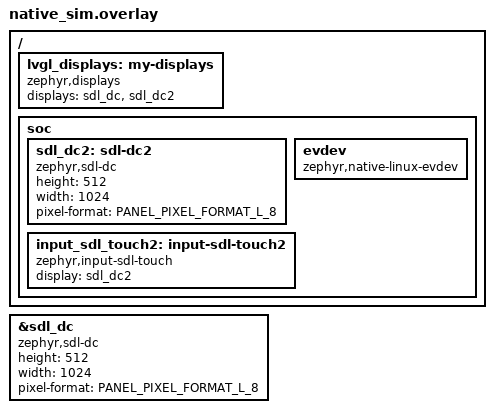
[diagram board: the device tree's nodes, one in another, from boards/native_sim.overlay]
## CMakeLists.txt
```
cmake_minimum_required(VERSION 3.20.0)

find_package(Zephyr REQUIRED HINTS $ENV{ZEPHYR_BASE})
project(3d_game_template_demo)

target_sources(app PRIVATE src/main.c src/editor_render.c src/editor_UI.c)

zephyr_include_directories(include)

set(TOOLS_FOLDER ${CMAKE_CURRENT_SOURCE_DIR}/../../../zephyr_3d_game_template2/tools)

add_custom_command(
OUTPUT generated/generated_objects.h
COMMAND python3 ${CMAKE_CURRENT_SOURCE_DIR}/generate_objects.py ${TOOLS_FOLDER} ${CMAKE_CURRENT_SOURCE_DIR}/${CONFIG_DATA_PATH} generated
WORKING_DIRECTORY ${CMAKE_CURRENT_BINARY_DIR}
)

add_custom_target(generate_objects DEPENDS generated/generated_objects.h)

zephyr_include_directories(${CMAKE_CURRENT_BINARY_DIR}/generated)

add_dependencies(app generate_objects)
```

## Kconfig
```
menu "Zephyr"
source "Kconfig.zephyr"
endmenu

module = VISUALIZER
module-str = VISUALIZER
source "subsys/logging/Kconfig.template.log_config"
```

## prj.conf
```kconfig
CONFIG_DISPLAY=y
CONFIG_LOG=y
CONFIG_ENGINE=y
#CONFIG_LOG_DEFAULT_LEVEL=4
CONFIG_HEAP_MEM_POOL_SIZE=65536
CONFIG_INPUT=y
CONFIG_MAIN_STACK_SIZE=65536
CONFIG_TIMING_FUNCTIONS=y
CONFIG_SPEED_OPTIMIZATIONS=y
CONFIG_LOG_PERFORMANCE=n
CONFIG_TEST_RANDOM_GENERATOR=y
CONFIG_TIMER_RANDOM_GENERATOR=y
CONFIG_GPIO=y
CONFIG_MAX_OBJECTS=1048576
CONFIG_BLIT_THREAD=n

CONFIG_LVGL=y
CONFIG_LV_USE_LOG=y
CONFIG_LV_Z_MEM_POOL_SIZE=131072
CONFIG_SYS_HEAP_RUNTIME_STATS=y

CONFIG_LV_FONT_MONTSERRAT_12=y
CONFIG_LV_Z_FLUSH_THREAD=y
CONFIG_LV_FONT_UNSCII_8=y

CONFIG_JSON_LIBRARY=y
#CONFIG_FLASH=y
#CONFIG_FILE_SYSTEM=y
#CONFIG_FUSE_FS_ACCESS=y
#CONFIG_FLASH_SIMULATOR=y
CONFIG_DATA_PATH="../../data"
```

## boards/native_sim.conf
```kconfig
CONFIG_SDL_DISPLAY_ZOOM_PCT=250
#CONFIG_SDL_DISPLAY_ZOOM_PCT=400
#CONFIG_SDL_DISPLAY_DEFAULT_PIXEL_FORMAT_RGB_565=y
CONFIG_RESOLUTION_X=1024
CONFIG_RESOLUTION_Y=512
CONFIG_TARGET_PROCESS_FPS=30
CONFIG_TARGET_RENDER_FPS=30
CONFIG_SYS_CLOCK_TICKS_PER_SEC=1000
```

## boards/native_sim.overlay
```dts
#include <zephyr/dt-bindings/input/input-event-codes.h>

&sdl_dc {
	compatible = "zephyr,sdl-dc";
	height = <512>;
	width = <1024>;
	pixel-format = <PANEL_PIXEL_FORMAT_L_8>;
};

/ {
	/delete-property/ zephyr,display;

	lvgl_displays: my-displays {
		compatible = "zephyr,displays";
		displays = <&sdl_dc &sdl_dc2>;
		status = "okay";
	};

	soc {
		sdl_dc2: sdl-dc2 {
			compatible = "zephyr,sdl-dc";
			height = <512>;
			width = <1024>;
			pixel-format = <PANEL_PIXEL_FORMAT_L_8>;
		};
		evdev: evdev {
			compatible = "zephyr,native-linux-evdev";
		};
		input_sdl_touch2: input-sdl-touch2 {
			compatible = "zephyr,input-sdl-touch";
			display = <&sdl_dc2>;
		};
	};
};
```

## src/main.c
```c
#include <zephyr/kernel.h>
#include <zephyr/device.h>
#include <zephyr/drivers/display.h>
#include <zephyr/input/input.h>
#include <zephyr/timing/timing.h>
#include <stdio.h>
#include <stdlib.h>
#include <zephyr/random/random.h>
#include <math.h>

#include <zephyr/logging/log.h>
LOG_MODULE_REGISTER(main);

#include "editor.h"

#include "engine.h"

L3_COLORTYPE blit_lvgl_buffer[L3_RESOLUTION_X * L3_RESOLUTION_Y];

int blit_display(L3_COLORTYPE *buffer, uint16_t x, uint16_t y, uint16_t size_x, uint16_t size_y)
{	/*struct display_buffer_descriptor buf_desc;
	buf_desc.buf_size = size_x * size_y;
		buf_desc.width = size_x;
	buf_desc.height = size_y;
	buf_desc.pitch = size_x;
		display_write(display_devices[0], 0, 0, &buf_desc, buffer);*/
	memcpy(blit_lvgl_buffer + x + y * L3_RESOLUTION_X, buffer, size_x*size_y);
	return 0;
}

typedef struct {
	L3_Unit vx;
	L3_Unit vy;
	L3_Unit z;
	L3_Unit x;
	L3_Unit speedmul;
	L3_Unit jump;
	L3_Unit xrot;
} Controls;

static Engine_Object* player = 0;
static Controls controls = {0};

static void process() {
	if (player != 0) {
		player->visual.transform.rotation.y += controls.vy;
		player->visual.transform.rotation.x += controls.vx;
		if (player->visual.transform.rotation.y > L3_F/2) player->visual.transform.rotation.y = -L3_F/2;
		if (player->visual.transform.rotation.y < -L3_F/2) player->visual.transform.rotation.y = L3_F/2;
		if (player->visual.transform.rotation.x > L3_F/2) player->visual.transform.rotation.x = -L3_F/2;
		if (player->visual.transform.rotation.x < -L3_F/2) player->visual.transform.rotation.x = L3_F/2;

		L3_Vec4 forward = {0, 0, L3_F, L3_F};
		L3_Vec4 left = {-L3_F, 0, 0, L3_F};
		L3_Mat4 transMat;

		L3_makeRotationMatrixZXY(player->visual.transform.rotation.x,
							player->visual.transform.rotation.y,
							0,
							transMat);

		L3_vec3Xmat4(&forward, transMat);
		L3_vec3Xmat4(&left, transMat);

		player->visual.transform.translation.x += controls.z * forward.x / L3_F;
		player->visual.transform.translation.y += controls.z * forward.y / L3_F;
		player->visual.transform.translation.z += controls.z * forward.z / L3_F;
		player->visual.transform.translation.x += controls.x * left.x / L3_F;
		player->visual.transform.translation.y += controls.x * left.y / L3_F;
		player->visual.transform.translation.z += controls.x * left.z / L3_F;

		L3_Camera *camera = engine_getcamera();
		camera->transform = player->visual.transform;
#ifdef CONFIG_SDL_DISPLAY
		printf("\r\b%d %d %d %d %d %d      ",
			camera->transform.translation.x,
			camera->transform.translation.y,
			camera->transform.translation.z,
			camera->transform.rotation.x,
			camera->transform.rotation.y,
			camera->transform.rotation.z);
#endif
	}

	do_editor_UI();
}

static void update_controls(struct input_event *evt, void *user_data)
{
	Controls *cont = user_data;

	if (evt->code == INPUT_KEY_UP) {
		if (evt->value)
			cont->vx = 5;
		else
			cont->vx = 0;
	} else if (evt->code == INPUT_KEY_DOWN) {
		if (evt->value)
			cont->vx = -5;
		else
			cont->vx = 0;
	}
	if (evt->code == INPUT_KEY_LEFT) {
		if (evt->value)
			cont->vy = 15;
		else
			cont->vy = 0;
	} else if (evt->code == INPUT_KEY_RIGHT) {
		if (evt->value)
			cont->vy = -15;
		else
			cont->vy = 0;
	}
	if (evt->code == INPUT_KEY_W) {
		if (evt->value)
			cont->z = E_SPEED(5*L3_F*cont->speedmul);
		else
			cont->z = 0;
	} else if (evt->code == INPUT_KEY_S) {
		if (evt->value)
			cont->z = -E_SPEED(5*L3_F*cont->speedmul);
		else
			cont->z = 0;
	}

	if (evt->code == INPUT_KEY_A) {
		if (evt->value)
			cont->x = E_SPEED(5*L3_F*cont->speedmul);
		else
			cont->x = 0;
	} else if (evt->code == INPUT_KEY_D) {
		if (evt->value)
			cont->x = -E_SPEED(5*L3_F*cont->speedmul);
		else
			cont->x = 0;
	}

	if (evt->code == INPUT_KEY_LEFTSHIFT) {
		if (evt->value)
			cont->speedmul = 8;
		else
			cont->speedmul = 1;
	}
}

INPUT_CALLBACK_DEFINE(0, update_controls, &controls);

int main()
{
	if (!device_is_ready(display_devices[0])) {
		printf("Display device not ready");
		return 0;
	}

	timing_init();
	timing_start();

	k_msleep(100);
	display_blanking_on(display_devices[0]);
	display_blanking_on(display_devices[1]);
	//display_blanking_on(display_devices[2]);
	//display_set_pixel_format(display_device, PIXEL_FORMAT_L_8);
	display_blanking_off(display_devices[0]);
	display_blanking_off(display_devices[1]);
	//display_blanking_off(display_devices[2]);

	init_engine(&process);
	engine_UI_set_area(0, 0, L3_RESOLUTION_X, L3_RESOLUTION_Y);
	init_editor_UI();

	//engine_getcamera()->focalLength = 12;

	/* 'player' object */
	Engine_Object tmp = {0};
	L3_transform3DSet(0 * L3_F,0,-8*L3_F,0,0,0,L3_F,L3_F,L3_F,&(tmp.visual.transform));
	tmp.view_range = 16 * L3_F;
	tmp.visual_type = ENGINE_VISUAL_NOTHING;
	player = engine_add_object(tmp);

	//engine_set_statics(demo_scene, sizeof(demo_scene) / sizeof(*demo_scene));
	//engine_statics_enabled(true);

	controls.speedmul = 1;

	printf("obj cnt: %d\n", engine_object_getcnt() + engine_statics_getcnt());

	return 0;
}
```

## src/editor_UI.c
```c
#include <zephyr/kernel.h>
#include <zephyr/device.h>
#include <zephyr/drivers/display.h>
#include <zephyr/input/input.h>
#include <zephyr/timing/timing.h>
#include <stdio.h>
#include <stdlib.h>
#include <zephyr/random/random.h>
#include <math.h>
#include <lvgl.h>
#include <lvgl_mem.h>
#include <lvgl_zephyr.h>

#include <zephyr/logging/log.h>
LOG_MODULE_REGISTER(editor_ui);

#include "editor.h"

#include "engine.h"

#include "generated_objects.h"

static lv_display_t *lv_displays[DT_ZEPHYR_DISPLAYS_COUNT];

static lv_display_t *lvgl_display;

Engine_Object *object;

static lv_obj_t *select_object_list;

lv_style_t style_transp;

lv_obj_t * background_render;
static lv_img_dsc_t background_render_img;
extern L3_COLORTYPE blit_lvgl_buffer[L3_RESOLUTION_X * L3_RESOLUTION_Y];

static void add_obj(lv_event_t * e)
{
	lv_event_code_t code = lv_event_get_code(e);
	lv_obj_t * obj = lv_event_get_target_obj(e);
	size_t id = (size_t)lv_event_get_user_data(e);
	if(code == LV_EVENT_CLICKED) {

		if (object != NULL)
		{
			engine_remove_object(object);
			engine_optimize_object_table();
			object = NULL;
		}

		object = engine_add_object(generated_object_list[id]);

		L3_transform3DSet(0, 0, 0,0,0,0,L3_F,L3_F,L3_F,&(object->visual.transform));
		object->view_range = 0x100000;
		if (object->collisions != NULL) {
		}
		if (object->visual_type == ENGINE_VISUAL_MODEL) {
			object->visual.config.visible |= L3_VISIBLE_NORMALDIFF;
		}
	}
}

int init_editor_UI(void)
{
	lv_display_t *d = NULL;

	/* inverted order for some reason */
	for (int i = 0; i < DT_ZEPHYR_DISPLAYS_COUNT; i++) {
		d = lv_display_get_next(d);
		if (d == NULL) {
			printf("Invalid LV display %d object", i);
			return 0;
		}
		lv_displays[i] = d;
	}
	lvgl_display = lv_displays[1];

	lv_display_set_default(lvgl_display);
	engine_UI_set_area(0, 0, L3_RESOLUTION_X, L3_RESOLUTION_Y);
	extern int set_lvgl_rendering_cb(lv_display_t *display);
	set_lvgl_rendering_cb(lvgl_display);

	background_render = lv_img_create(lv_screen_active());
	background_render_img.header.magic = LV_IMAGE_HEADER_MAGIC;
	background_render_img.header.w = L3_RESOLUTION_X;
	background_render_img.header.h = L3_RESOLUTION_Y;
	background_render_img.data_size = L3_RESOLUTION_X * L3_RESOLUTION_Y;
	background_render_img.header.cf = LV_COLOR_FORMAT_L8;
	background_render_img.data = (uint8_t *)blit_lvgl_buffer;
	lv_img_set_src(background_render, &background_render_img);
	lv_obj_set_size(background_render, 1024, 512);
	lv_obj_center(background_render);

	select_object_list = lv_list_create(lv_screen_active());
	lv_obj_set_size(select_object_list, 256, 512);
	lv_obj_align(select_object_list, LV_ALIGN_TOP_RIGHT, 0,0);


	lv_style_init(&style_transp);
	lv_style_set_bg_opa(&style_transp, LV_OPA_TRANSP);
	//lv_style_set_border_width(&style_transp, 0);
	lv_style_set_text_color(&style_transp, lv_color_hex3(0xFFF));
	lv_style_set_radius(&style_transp, 0);
	lv_style_set_border_width(&style_transp, 1);
	lv_style_set_pad_all(&style_transp, 1);
	lv_obj_add_style(select_object_list, &style_transp, 0);

	for (int i = 0; i < ARRAY_SIZE(generated_object_list); i++) {
		lv_obj_t * btn;
		btn = lv_list_add_button(select_object_list, NULL, generated_object_list_names[i]);
		lv_obj_add_style(btn, &style_transp, 0);
		lv_obj_add_event_cb(btn, add_obj, LV_EVENT_CLICKED, (void*)i);
	}

	return 0;
}

int do_editor_UI(void)
{
	lv_display_set_default(lvgl_display);

	lv_img_set_src(background_render, &background_render_img);
	lv_timer_handler();

	return 0;
}
```
